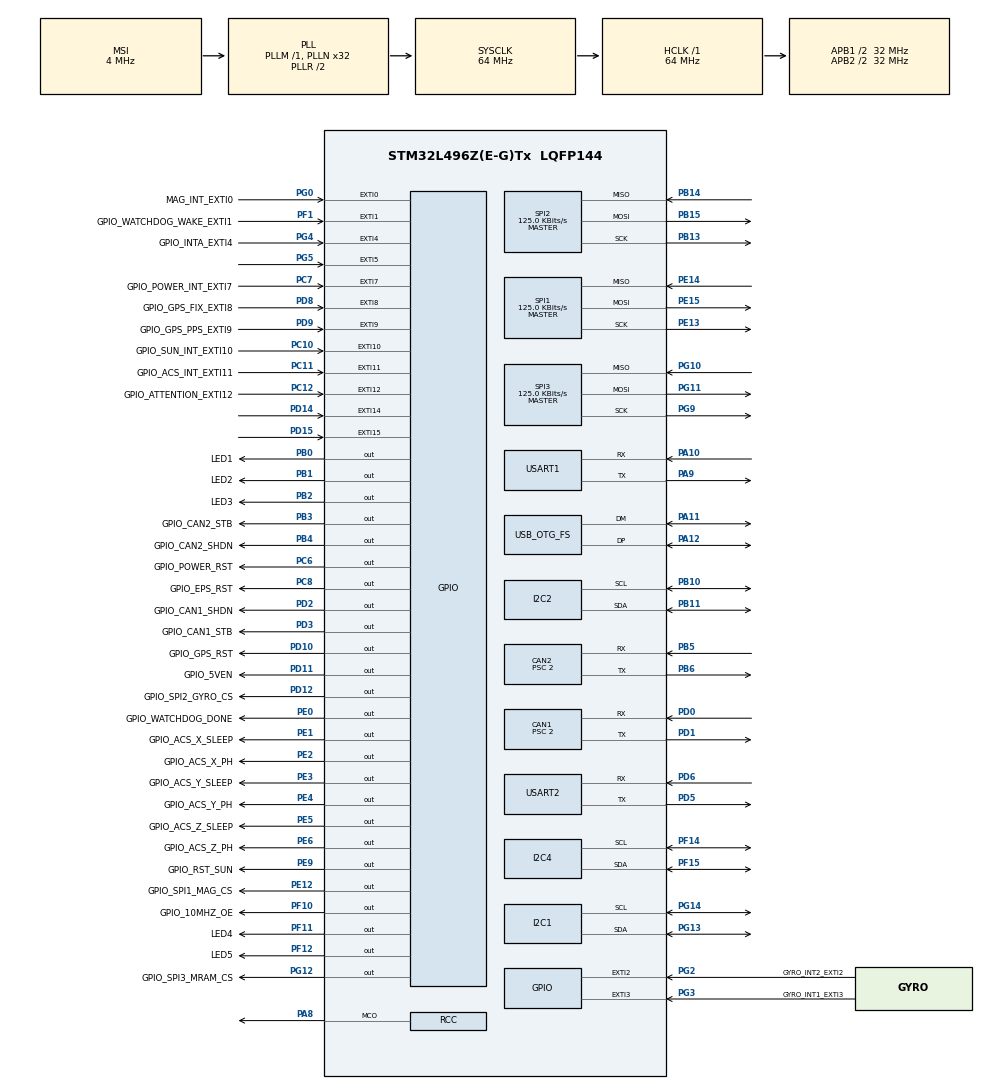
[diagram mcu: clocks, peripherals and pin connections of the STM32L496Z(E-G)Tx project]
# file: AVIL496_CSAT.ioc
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CAN1.AWUM=ENABLE
CAN1.BS1=CAN_BS1_13TQ
CAN1.BS2=CAN_BS2_2TQ
CAN1.CalculateBaudRate=1000000
CAN1.CalculateTimeBit=1000
CAN1.CalculateTimeQuantum=62.5
CAN1.Prescaler=2
CAN2.AWUM=ENABLE
CAN2.BS1=CAN_BS1_13TQ
CAN2.BS2=CAN_BS2_2TQ
CAN2.CalculateBaudRate=1000000
CAN2.CalculateTimeBit=1000
CAN2.CalculateTimeQuantum=62.5
CAN2.Prescaler=2
I2C1.Timing=0x00B07CB4
I2C2.Timing=0x00B07CB4
I2C4.Timing=0x00B07CB4
Mcu.Family=STM32L4
Mcu.Name=STM32L496Z(E-G)Tx
Mcu.Package=LQFP144
NVIC.CAN1_RX0_IRQn=true\:0\:0\:false\:false\:true\:true\:true\:true
NVIC.CAN1_RX1_IRQn=true\:0\:0\:false\:false\:true\:true\:true\:true
NVIC.CAN1_SCE_IRQn=true\:0\:0\:false\:false\:true\:true\:true\:true
NVIC.CAN2_RX0_IRQn=true\:0\:0\:false\:false\:true\:true\:true\:true
NVIC.CAN2_RX1_IRQn=true\:0\:0\:false\:false\:true\:true\:true\:true
NVIC.CAN2_SCE_IRQn=true\:0\:0\:false\:false\:true\:true\:true\:true
NVIC.EXTI0_IRQn=true\:0\:0\:false\:false\:true\:true\:true\:true
NVIC.EXTI15_10_IRQn=true\:0\:0\:false\:false\:true\:true\:true\:true
NVIC.EXTI1_IRQn=true\:0\:0\:false\:false\:true\:true\:true\:true
NVIC.EXTI2_IRQn=true\:0\:0\:false\:false\:true\:true\:true\:true
NVIC.EXTI3_IRQn=true\:0\:0\:false\:false\:true\:true\:true\:true
NVIC.EXTI4_IRQn=true\:0\:0\:false\:false\:true\:true\:true\:true
NVIC.EXTI9_5_IRQn=true\:0\:0\:false\:false\:true\:true\:true\:true
NVIC.OTG_FS_IRQn=true\:0\:0\:false\:false\:true\:false\:true\:true
NVIC.PriorityGroup=NVIC_PRIORITYGROUP_4
PA0.Signal=ADCx_IN5
PA1.Signal=ADCx_IN6
PA10.Mode=Asynchronous
PA10.Signal=USART1_RX
PA11.Mode=Device_Only
PA11.Signal=USB_OTG_FS_DM
PA12.Mode=Device_Only
PA12.Signal=USB_OTG_FS_DP
PA13\ (JTMS/SWDIO).Signal=SYS_JTMS-SWDIO
PA14\ (JTCK/SWCLK).Signal=SYS_JTCK-SWCLK
PA2.Signal=ADCx_IN7
PA3.Signal=ADCx_IN8
PA4.Signal=ADCx_IN9
PA5.Signal=ADCx_IN10
PA6.Signal=ADCx_IN11
PA7.Signal=ADCx_IN12
PA8.Mode=Clock-out
PA8.Signal=RCC_MCO
PA9.Mode=Asynchronous
PA9.Signal=USART1_TX
PB0.GPIO_Label=LED1
PB0.Signal=GPIO_Output
PB1.GPIO_Label=LED2
PB1.Signal=GPIO_Output
PB10.Mode=I2C
PB10.Signal=I2C2_SCL
PB11.Mode=I2C
PB11.Signal=I2C2_SDA
PB13.Mode=Full_Duplex_Master
PB13.Signal=SPI2_SCK
PB14.Mode=Full_Duplex_Master
PB14.Signal=SPI2_MISO
PB15.Mode=Full_Duplex_Master
PB15.Signal=SPI2_MOSI
PB2.GPIO_Label=LED3
PB2.Signal=GPIO_Output
PB3\ (JTDO/TRACESWO).GPIO_Label=GPIO_CAN2_STB
PB3\ (JTDO/TRACESWO).Signal=GPIO_Output
PB4\ (NJTRST).GPIO_Label=GPIO_CAN2_SHDN
PB4\ (NJTRST).Signal=GPIO_Output
PB5.Mode=CAN_Activate
PB5.Signal=CAN2_RX
PB6.Mode=CAN_Activate
PB6.Signal=CAN2_TX
PB8.GPIO_Label=TIM16_CH1_ACS_X
PB8.Signal=S_TIM16_CH1
PB9.GPIO_Label=TIM17_CH1_ACS_Y
PB9.Signal=S_TIM17_CH1
PC10.GPIO_Label=GPIO_SUN_INT_EXTI10
PC10.Signal=GPXTI10
PC11.GPIO_Label=GPIO_ACS_INT_EXTI11
PC11.Signal=GPXTI11
PC12.GPIO_Label=GPIO_ATTENTION_EXTI12
PC12.Signal=GPXTI12
PC14-OSC32_IN\ (PC14).Mode=LSE-External-Clock-Source
PC14-OSC32_IN\ (PC14).Signal=RCC_OSC32_IN
PC2.Signal=ADCx_IN3
PC3.Signal=ADCx_IN4
PC6.GPIO_Label=GPIO_POWER_RST
PC6.Signal=GPIO_Output
PC7.GPIO_Label=GPIO_POWER_INT_EXTI7
PC7.Signal=GPXTI7
PC8.GPIO_Label=GPIO_EPS_RST
PC8.Signal=GPIO_Output
PD0.Mode=CAN_Activate
PD0.Signal=CAN1_RX
PD1.Mode=CAN_Activate
PD1.Signal=CAN1_TX
PD10.GPIO_Label=GPIO_GPS_RST
PD10.Signal=GPIO_Output
PD11.GPIO_Label=GPIO_5VEN
PD11.Signal=GPIO_Output
PD12.GPIO_Label=GPIO_SPI2_GYRO_CS
PD12.PinState=GPIO_PIN_SET
PD12.Signal=GPIO_Output
PD14.Signal=GPXTI14
PD15.Signal=GPXTI15
PD2.GPIO_Label=GPIO_CAN1_SHDN
PD2.Signal=GPIO_Output
PD3.GPIO_Label=GPIO_CAN1_STB
PD3.Signal=GPIO_Output
PD5.Mode=Asynchronous
PD5.Signal=USART2_TX
PD6.Mode=Asynchronous
PD6.Signal=USART2_RX
PD8.GPIO_Label=GPIO_GPS_FIX_EXTI8
PD8.Signal=GPXTI8
PD9.GPIO_Label=GPIO_GPS_PPS_EXTI9
PD9.Signal=GPXTI9
PE0.GPIO_Label=GPIO_WATCHDOG_DONE
PE0.Signal=GPIO_Output
PE1.GPIO_Label=GPIO_ACS_X_SLEEP
PE1.Signal=GPIO_Output
PE12.GPIO_Label=GPIO_SPI1_MAG_CS
PE12.PinState=GPIO_PIN_SET
PE12.Signal=GPIO_Output
PE13.Mode=Full_Duplex_Master
PE13.Signal=SPI1_SCK
PE14.Mode=Full_Duplex_Master
PE14.Signal=SPI1_MISO
PE15.Mode=Full_Duplex_Master
PE15.Signal=SPI1_MOSI
PE2.GPIO_Label=GPIO_ACS_X_PH
PE2.Signal=GPIO_Output
PE3.GPIO_Label=GPIO_ACS_Y_SLEEP
PE3.Signal=GPIO_Output
PE4.GPIO_Label=GPIO_ACS_Y_PH
PE4.Signal=GPIO_Output
PE5.GPIO_Label=GPIO_ACS_Z_SLEEP
PE5.Signal=GPIO_Output
PE6.GPIO_Label=GPIO_ACS_Z_PH
PE6.Signal=GPIO_Output
PE9.GPIO_Label=GPIO_RST_SUN
PE9.Signal=GPIO_Output
PF1.GPIO_Label=GPIO_WATCHDOG_WAKE_EXTI1
PF1.GPIO_ModeDefaultEXTI=GPIO_MODE_IT_RISING
PF1.Signal=GPXTI1
PF10.GPIO_Label=GPIO_10MHZ_OE
PF10.Signal=GPIO_Output
PF11.GPIO_Label=LED4
PF11.Signal=GPIO_Output
PF12.GPIO_Label=LED5
PF12.Signal=GPIO_Output
PF14.Mode=I2C
PF14.Signal=I2C4_SCL
PF15.Mode=I2C
PF15.Signal=I2C4_SDA
PF9.GPIO_Label=TIM15_CHi1_ACS_Z
PF9.Signal=S_TIM15_CH1
PG0.GPIO_Label=MAG_INT_EXTI0
PG0.Signal=GPXTI0
PG10.Mode=Full_Duplex_Master
PG10.Signal=SPI3_MISO
PG11.Mode=Full_Duplex_Master
PG11.Signal=SPI3_MOSI
PG12.GPIO_Label=GPIO_SPI3_MRAM_CS
PG12.Signal=GPIO_Output
PG13.Mode=I2C
PG13.Signal=I2C1_SDA
PG14.Mode=I2C
PG14.Signal=I2C1_SCL
PG2.GPIO_Label=GYRO_INT2_EXTI2
PG2.Signal=GPXTI2
PG3.GPIO_Label=GYRO_INT1_EXTI3
PG3.Signal=GPXTI3
PG4.GPIO_Label=GPIO_INTA_EXTI4
PG4.Signal=GPXTI4
PG5.Signal=GPXTI5
PG9.Mode=Full_Duplex_Master
PG9.Signal=SPI3_SCK
PH0-OSC_IN\ (PH0).Signal=RCC_OSC_IN
ProjectManager.HeapSize=0x200
ProjectManager.StackSize=0x400
ProjectManager.TargetToolchain=STM32CubeIDE
RCC.ADCFreq_Value=48000000
RCC.AHBFreq_Value=64000000
RCC.APB1CLKDivider=RCC_HCLK_DIV2
RCC.APB1Freq_Value=32000000
RCC.APB1TimFreq_Value=64000000
RCC.APB2CLKDivider=RCC_HCLK_DIV2
RCC.APB2Freq_Value=32000000
RCC.APB2TimFreq_Value=64000000
RCC.CortexFreq_Value=64000000
RCC.HCLKFreq_Value=64000000
RCC.HSE_VALUE=8000000
RCC.HSI48_VALUE=48000000
RCC.HSI_VALUE=16000000
RCC.LSE_VALUE=32768
RCC.MSI_VALUE=4000000
RCC.PLLN=32
RCC.PLLSAI1N=24
RCC.SYSCLKFreq_VALUE=64000000
RCC.SYSCLKSource=RCC_SYSCLKSOURCE_PLLCLK
RCC.USBFreq_Value=48000000
RCC.VCOOutputFreq_Value=128000000
SH.ADCx_IN10.0=ADC1_IN10
SH.ADCx_IN11.0=ADC1_IN11
SH.ADCx_IN12.0=ADC1_IN12
SH.ADCx_IN3.0=ADC1_IN3
SH.ADCx_IN4.0=ADC1_IN4
SH.ADCx_IN5.0=ADC1_IN5
SH.ADCx_IN6.0=ADC1_IN6
SH.ADCx_IN7.0=ADC1_IN7
SH.ADCx_IN8.0=ADC1_IN8
SH.ADCx_IN9.0=ADC1_IN9
SH.S_TIM15_CH1.0=TIM15_CH1
SH.S_TIM16_CH1.0=TIM16_CH1
SH.S_TIM17_CH1.0=TIM17_CH1
SPI1.BaudRatePrescaler=SPI_BAUDRATEPRESCALER_256
SPI1.CalculateBaudRate=125.0 KBits/s
SPI1.DataSize=SPI_DATASIZE_8BIT
SPI1.Direction=SPI_DIRECTION_2LINES
SPI1.Mode=SPI_MODE_MASTER
SPI1.VirtualType=VM_MASTER
SPI2.BaudRatePrescaler=SPI_BAUDRATEPRESCALER_256
SPI2.CalculateBaudRate=125.0 KBits/s
SPI2.DataSize=SPI_DATASIZE_8BIT
SPI2.Direction=SPI_DIRECTION_2LINES
SPI2.Mode=SPI_MODE_MASTER
SPI2.VirtualType=VM_MASTER
SPI3.BaudRatePrescaler=SPI_BAUDRATEPRESCALER_256
SPI3.CalculateBaudRate=125.0 KBits/s
SPI3.DataSize=SPI_DATASIZE_8BIT
SPI3.Direction=SPI_DIRECTION_2LINES
SPI3.Mode=SPI_MODE_MASTER
SPI3.VirtualType=VM_MASTER
USART1.VirtualMode-Asynchronous=VM_ASYNC
USART2.VirtualMode-Asynchronous=VM_ASYNC
USB_DEVICE.CLASS_NAME_FS=CDC
USB_DEVICE.VirtualMode=Cdc
USB_DEVICE.VirtualModeFS=Cdc_FS
USB_OTG_FS.VirtualMode=Device_Only
VP_RTC_VS_RTC_Activate.Mode=RTC_Enabled
VP_USB_DEVICE_VS_USB_DEVICE_CDC_FS.Mode=CDC_FS
board=custom

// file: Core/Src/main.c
/* USER CODE BEGIN Header */
/**
  ******************************************************************************
  * @file           : main.c
  * @brief          : Main program body
  ******************************************************************************
  * @attention
  *
  * Copyright (c) 2025 STMicroelectronics.
  * All rights reserved.
  *
  * This software is licensed under terms that can be found in the LICENSE file
  * in the root directory of this software component.
  * If no LICENSE file comes with this software, it is provided AS-IS.
  *
  ******************************************************************************
  */
/* USER CODE END Header */
#include "main.h"
#include "usb_device.h"

/* USER CODE BEGIN Includes */
#include "cppmain.h"
#include "usbd_cdc_if.h"
/* USER CODE END Includes */

CAN_HandleTypeDef hcan1;
CAN_HandleTypeDef hcan2;

I2C_HandleTypeDef hi2c1;
I2C_HandleTypeDef hi2c2;
I2C_HandleTypeDef hi2c4;

RTC_HandleTypeDef hrtc;

SPI_HandleTypeDef hspi1;
SPI_HandleTypeDef hspi2;
SPI_HandleTypeDef hspi3;

UART_HandleTypeDef huart1;
UART_HandleTypeDef huart2;

void SystemClock_Config(void);
static void MX_GPIO_Init(void);
static void MX_CAN1_Init(void);
static void MX_CAN2_Init(void);
static void MX_I2C1_Init(void);
static void MX_I2C2_Init(void);
static void MX_I2C4_Init(void);
static void MX_USART1_UART_Init(void);
static void MX_USART2_UART_Init(void);
static void MX_RTC_Init(void);
static void MX_SPI1_Init(void);
static void MX_SPI2_Init(void);
static void MX_SPI3_Init(void);
/* USER CODE BEGIN PFP */
void SendWatchDogDone();
/* USER CODE END PFP */

/* USER CODE BEGIN 0 */
extern int getentropy(void* buffer, size_t length) {
    (void)buffer;
    (void)length;
    return -1; // ENOSYS: Function not implemented
}
/* USER CODE END 0 */

int main(void)
{

  /* MCU Configuration--------------------------------------------------------*/

  /* Reset of all peripherals, Initializes the Flash interface and the Systick. */
  HAL_Init();

  /* Configure the system clock */
  SystemClock_Config();

  /* Initialize all configured peripherals */
  MX_GPIO_Init();
  MX_CAN1_Init();
  MX_CAN2_Init();
  MX_I2C1_Init();
  MX_I2C2_Init();
  MX_I2C4_Init();
  MX_USART1_UART_Init();
  MX_USART2_UART_Init();
  MX_USB_DEVICE_Init();
  MX_RTC_Init();
  MX_SPI1_Init();
  MX_SPI2_Init();
  MX_SPI3_Init();
  /* USER CODE BEGIN 2 */
  SendWatchDogDone();
  cppmain();
  /* USER CODE END 2 */

  /* Infinite loop */
  while (1)
  {

  }
}

void SystemClock_Config(void)
{
  RCC_OscInitTypeDef RCC_OscInitStruct = {0};
  RCC_ClkInitTypeDef RCC_ClkInitStruct = {0};

  /** Configure the main internal regulator output voltage
  */
  if (HAL_PWREx_ControlVoltageScaling(PWR_REGULATOR_VOLTAGE_SCALE1) != HAL_OK)
  {
    Error_Handler();
  }

  /** Initializes the RCC Oscillators according to the specified parameters
  * in the RCC_OscInitTypeDef structure.
  */
  RCC_OscInitStruct.OscillatorType = RCC_OSCILLATORTYPE_LSI|RCC_OSCILLATORTYPE_LSE
                              |RCC_OSCILLATORTYPE_MSI;
  RCC_OscInitStruct.LSEState = RCC_LSE_BYPASS;
  RCC_OscInitStruct.LSIState = RCC_LSI_ON;
  RCC_OscInitStruct.MSIState = RCC_MSI_ON;
  RCC_OscInitStruct.MSICalibrationValue = 0;
  RCC_OscInitStruct.MSIClockRange = RCC_MSIRANGE_6;
  RCC_OscInitStruct.PLL.PLLState = RCC_PLL_ON;
  RCC_OscInitStruct.PLL.PLLSource = RCC_PLLSOURCE_MSI;
  RCC_OscInitStruct.PLL.PLLM = 1;
  RCC_OscInitStruct.PLL.PLLN = 32;
  RCC_OscInitStruct.PLL.PLLP = RCC_PLLP_DIV2;
  RCC_OscInitStruct.PLL.PLLQ = RCC_PLLQ_DIV2;
  RCC_OscInitStruct.PLL.PLLR = RCC_PLLR_DIV2;
  if (HAL_RCC_OscConfig(&RCC_OscInitStruct) != HAL_OK)
  {
    Error_Handler();
  }

  /** Initializes the CPU, AHB and APB buses clocks
  */
  RCC_ClkInitStruct.ClockType = RCC_CLOCKTYPE_HCLK|RCC_CLOCKTYPE_SYSCLK
                              |RCC_CLOCKTYPE_PCLK1|RCC_CLOCKTYPE_PCLK2;
  RCC_ClkInitStruct.SYSCLKSource = RCC_SYSCLKSOURCE_PLLCLK;
  RCC_ClkInitStruct.AHBCLKDivider = RCC_SYSCLK_DIV1;
  RCC_ClkInitStruct.APB1CLKDivider = RCC_HCLK_DIV2;
  RCC_ClkInitStruct.APB2CLKDivider = RCC_HCLK_DIV2;

  if (HAL_RCC_ClockConfig(&RCC_ClkInitStruct, FLASH_LATENCY_3) != HAL_OK)
  {
    Error_Handler();
  }
  HAL_RCC_MCOConfig(RCC_MCO1, RCC_MCO1SOURCE_SYSCLK, RCC_MCODIV_1);

  /** Enable MSI Auto calibration
  */
  HAL_RCCEx_EnableMSIPLLMode();
}

static void MX_CAN1_Init(void)
{

  hcan1.Instance = CAN1;
  hcan1.Init.Prescaler = 2;
  hcan1.Init.Mode = CAN_MODE_NORMAL;
  hcan1.Init.SyncJumpWidth = CAN_SJW_1TQ;
  hcan1.Init.TimeSeg1 = CAN_BS1_13TQ;
  hcan1.Init.TimeSeg2 = CAN_BS2_2TQ;
  hcan1.Init.TimeTriggeredMode = DISABLE;
  hcan1.Init.AutoBusOff = DISABLE;
  hcan1.Init.AutoWakeUp = ENABLE;
  hcan1.Init.AutoRetransmission = DISABLE;
  hcan1.Init.ReceiveFifoLocked = DISABLE;
  hcan1.Init.TransmitFifoPriority = DISABLE;
  if (HAL_CAN_Init(&hcan1) != HAL_OK)
  {
    Error_Handler();
  }

}

static void MX_CAN2_Init(void)
{

  hcan2.Instance = CAN2;
  hcan2.Init.Prescaler = 2;
  hcan2.Init.Mode = CAN_MODE_NORMAL;
  hcan2.Init.SyncJumpWidth = CAN_SJW_1TQ;
  hcan2.Init.TimeSeg1 = CAN_BS1_13TQ;
  hcan2.Init.TimeSeg2 = CAN_BS2_2TQ;
  hcan2.Init.TimeTriggeredMode = DISABLE;
  hcan2.Init.AutoBusOff = DISABLE;
  hcan2.Init.AutoWakeUp = ENABLE;
  hcan2.Init.AutoRetransmission = DISABLE;
  hcan2.Init.ReceiveFifoLocked = DISABLE;
  hcan2.Init.TransmitFifoPriority = DISABLE;
  if (HAL_CAN_Init(&hcan2) != HAL_OK)
  {
    Error_Handler();
  }

}

static void MX_I2C1_Init(void)
{

  hi2c1.Instance = I2C1;
  hi2c1.Init.Timing = 0x00B07CB4;
  hi2c1.Init.OwnAddress1 = 0;
  hi2c1.Init.AddressingMode = I2C_ADDRESSINGMODE_7BIT;
  hi2c1.Init.DualAddressMode = I2C_DUALADDRESS_DISABLE;
  hi2c1.Init.OwnAddress2 = 0;
  hi2c1.Init.OwnAddress2Masks = I2C_OA2_NOMASK;
  hi2c1.Init.GeneralCallMode = I2C_GENERALCALL_DISABLE;
  hi2c1.Init.NoStretchMode = I2C_NOSTRETCH_DISABLE;
  if (HAL_I2C_Init(&hi2c1) != HAL_OK)
  {
    Error_Handler();
  }

  /** Configure Analogue filter
  */
  if (HAL_I2CEx_ConfigAnalogFilter(&hi2c1, I2C_ANALOGFILTER_ENABLE) != HAL_OK)
  {
    Error_Handler();
  }

  /** Configure Digital filter
  */
  if (HAL_I2CEx_ConfigDigitalFilter(&hi2c1, 0) != HAL_OK)
  {
    Error_Handler();
  }

}

static void MX_I2C2_Init(void)
{

  hi2c2.Instance = I2C2;
  hi2c2.Init.Timing = 0x00B07CB4;
  hi2c2.Init.OwnAddress1 = 0;
  hi2c2.Init.AddressingMode = I2C_ADDRESSINGMODE_7BIT;
  hi2c2.Init.DualAddressMode = I2C_DUALADDRESS_DISABLE;
  hi2c2.Init.OwnAddress2 = 0;
  hi2c2.Init.OwnAddress2Masks = I2C_OA2_NOMASK;
  hi2c2.Init.GeneralCallMode = I2C_GENERALCALL_DISABLE;
  hi2c2.Init.NoStretchMode = I2C_NOSTRETCH_DISABLE;
  if (HAL_I2C_Init(&hi2c2) != HAL_OK)
  {
    Error_Handler();
  }

  /** Configure Analogue filter
  */
  if (HAL_I2CEx_ConfigAnalogFilter(&hi2c2, I2C_ANALOGFILTER_ENABLE) != HAL_OK)
  {
    Error_Handler();
  }

  /** Configure Digital filter
  */
  if (HAL_I2CEx_ConfigDigitalFilter(&hi2c2, 0) != HAL_OK)
  {
    Error_Handler();
  }

}

static void MX_I2C4_Init(void)
{

  hi2c4.Instance = I2C4;
  hi2c4.Init.Timing = 0x00B07CB4;
  hi2c4.Init.OwnAddress1 = 0;
  hi2c4.Init.AddressingMode = I2C_ADDRESSINGMODE_7BIT;
  hi2c4.Init.DualAddressMode = I2C_DUALADDRESS_DISABLE;
  hi2c4.Init.OwnAddress2 = 0;
  hi2c4.Init.OwnAddress2Masks = I2C_OA2_NOMASK;
  hi2c4.Init.GeneralCallMode = I2C_GENERALCALL_DISABLE;
  hi2c4.Init.NoStretchMode = I2C_NOSTRETCH_DISABLE;
  if (HAL_I2C_Init(&hi2c4) != HAL_OK)
  {
    Error_Handler();
  }

  /** Configure Analogue filter
  */
  if (HAL_I2CEx_ConfigAnalogFilter(&hi2c4, I2C_ANALOGFILTER_ENABLE) != HAL_OK)
  {
    Error_Handler();
  }

  /** Configure Digital filter
  */
  if (HAL_I2CEx_ConfigDigitalFilter(&hi2c4, 0) != HAL_OK)
  {
    Error_Handler();
  }

}

static void MX_RTC_Init(void)
{

  /** Initialize RTC Only
  */
  hrtc.Instance = RTC;
  hrtc.Init.HourFormat = RTC_HOURFORMAT_24;
  hrtc.Init.AsynchPrediv = 127;
  hrtc.Init.SynchPrediv = 255;
  hrtc.Init.OutPut = RTC_OUTPUT_DISABLE;
  hrtc.Init.OutPutRemap = RTC_OUTPUT_REMAP_NONE;
  hrtc.Init.OutPutPolarity = RTC_OUTPUT_POLARITY_HIGH;
  hrtc.Init.OutPutType = RTC_OUTPUT_TYPE_OPENDRAIN;
  if (HAL_RTC_Init(&hrtc) != HAL_OK)
  {
    Error_Handler();
  }

}

static void MX_SPI1_Init(void)
{

  /* SPI1 parameter configuration*/
  hspi1.Instance = SPI1;
  hspi1.Init.Mode = SPI_MODE_MASTER;
  hspi1.Init.Direction = SPI_DIRECTION_2LINES;
  hspi1.Init.DataSize = SPI_DATASIZE_8BIT;
  hspi1.Init.CLKPolarity = SPI_POLARITY_LOW;
  hspi1.Init.CLKPhase = SPI_PHASE_1EDGE;
  hspi1.Init.NSS = SPI_NSS_SOFT;
  hspi1.Init.BaudRatePrescaler = SPI_BAUDRATEPRESCALER_256;
  hspi1.Init.FirstBit = SPI_FIRSTBIT_MSB;
  hspi1.Init.TIMode = SPI_TIMODE_DISABLE;
  hspi1.Init.CRCCalculation = SPI_CRCCALCULATION_DISABLE;
  hspi1.Init.CRCPolynomial = 7;
  hspi1.Init.CRCLength = SPI_CRC_LENGTH_DATASIZE;
  hspi1.Init.NSSPMode = SPI_NSS_PULSE_ENABLE;
  if (HAL_SPI_Init(&hspi1) != HAL_OK)
  {
    Error_Handler();
  }

}

static void MX_SPI2_Init(void)
{

  /* SPI2 parameter configuration*/
  hspi2.Instance = SPI2;
  hspi2.Init.Mode = SPI_MODE_MASTER;
  hspi2.Init.Direction = SPI_DIRECTION_2LINES;
  hspi2.Init.DataSize = SPI_DATASIZE_8BIT;
  hspi2.Init.CLKPolarity = SPI_POLARITY_LOW;
  hspi2.Init.CLKPhase = SPI_PHASE_1EDGE;
  hspi2.Init.NSS = SPI_NSS_SOFT;
  hspi2.Init.BaudRatePrescaler = SPI_BAUDRATEPRESCALER_256;
  hspi2.Init.FirstBit = SPI_FIRSTBIT_MSB;
  hspi2.Init.TIMode = SPI_TIMODE_DISABLE;
  hspi2.Init.CRCCalculation = SPI_CRCCALCULATION_DISABLE;
  hspi2.Init.CRCPolynomial = 7;
  hspi2.Init.CRCLength = SPI_CRC_LENGTH_DATASIZE;
  hspi2.Init.NSSPMode = SPI_NSS_PULSE_ENABLE;
  if (HAL_SPI_Init(&hspi2) != HAL_OK)
  {
    Error_Handler();
  }

}

static void MX_SPI3_Init(void)
{

  /* SPI3 parameter configuration*/
  hspi3.Instance = SPI3;
  hspi3.Init.Mode = SPI_MODE_MASTER;
  hspi3.Init.Direction = SPI_DIRECTION_2LINES;
  hspi3.Init.DataSize = SPI_DATASIZE_8BIT;
  hspi3.Init.CLKPolarity = SPI_POLARITY_LOW;
  hspi3.Init.CLKPhase = SPI_PHASE_1EDGE;
  hspi3.Init.NSS = SPI_NSS_SOFT;
  hspi3.Init.BaudRatePrescaler = SPI_BAUDRATEPRESCALER_256;
  hspi3.Init.FirstBit = SPI_FIRSTBIT_MSB;
  hspi3.Init.TIMode = SPI_TIMODE_DISABLE;
  hspi3.Init.CRCCalculation = SPI_CRCCALCULATION_DISABLE;
  hspi3.Init.CRCPolynomial = 7;
  hspi3.Init.CRCLength = SPI_CRC_LENGTH_DATASIZE;
  hspi3.Init.NSSPMode = SPI_NSS_PULSE_ENABLE;
  if (HAL_SPI_Init(&hspi3) != HAL_OK)
  {
    Error_Handler();
  }

}

static void MX_USART1_UART_Init(void)
{

  huart1.Instance = USART1;
  huart1.Init.BaudRate = 115200;
  huart1.Init.WordLength = UART_WORDLENGTH_8B;
  huart1.Init.StopBits = UART_STOPBITS_1;
  huart1.Init.Parity = UART_PARITY_NONE;
  huart1.Init.Mode = UART_MODE_TX_RX;
  huart1.Init.HwFlowCtl = UART_HWCONTROL_NONE;
  huart1.Init.OverSampling = UART_OVERSAMPLING_16;
  huart1.Init.OneBitSampling = UART_ONE_BIT_SAMPLE_DISABLE;
  huart1.AdvancedInit.AdvFeatureInit = UART_ADVFEATURE_NO_INIT;
  if (HAL_UART_Init(&huart1) != HAL_OK)
  {
    Error_Handler();
  }

}

static void MX_USART2_UART_Init(void)
{

  huart2.Instance = USART2;
  huart2.Init.BaudRate = 115200;
  huart2.Init.WordLength = UART_WORDLENGTH_8B;
  huart2.Init.StopBits = UART_STOPBITS_1;
  huart2.Init.Parity = UART_PARITY_NONE;
  huart2.Init.Mode = UART_MODE_TX_RX;
  huart2.Init.HwFlowCtl = UART_HWCONTROL_NONE;
  huart2.Init.OverSampling = UART_OVERSAMPLING_16;
  huart2.Init.OneBitSampling = UART_ONE_BIT_SAMPLE_DISABLE;
  huart2.AdvancedInit.AdvFeatureInit = UART_ADVFEATURE_NO_INIT;
  if (HAL_UART_Init(&huart2) != HAL_OK)
  {
    Error_Handler();
  }

}

static void MX_GPIO_Init(void)
{
  GPIO_InitTypeDef GPIO_InitStruct = {0};

  /* GPIO Ports Clock Enable */
  __HAL_RCC_GPIOE_CLK_ENABLE();
  __HAL_RCC_GPIOC_CLK_ENABLE();
  __HAL_RCC_GPIOF_CLK_ENABLE();
  __HAL_RCC_GPIOH_CLK_ENABLE();
  __HAL_RCC_GPIOA_CLK_ENABLE();
  __HAL_RCC_GPIOB_CLK_ENABLE();
  __HAL_RCC_GPIOG_CLK_ENABLE();
  __HAL_RCC_GPIOD_CLK_ENABLE();
  HAL_PWREx_EnableVddIO2();

  /*Configure GPIO pin Output Level */
  HAL_GPIO_WritePin(GPIOE, GPIO_ACS_X_PH_Pin|GPIO_ACS_Y_SLEEP_Pin|GPIO_ACS_Y_PH_Pin|GPIO_ACS_Z_SLEEP_Pin
                          |GPIO_ACS_Z_PH_Pin|GPIO_RST_SUN_Pin|GPIO_WATCHDOG_DONE_Pin|GPIO_ACS_X_SLEEP_Pin, GPIO_PIN_RESET);

  /*Configure GPIO pin Output Level */
  HAL_GPIO_WritePin(GPIOF, GPIO_10MHZ_OE_Pin|LED4_Pin|LED5_Pin, GPIO_PIN_RESET);

  /*Configure GPIO pin Output Level */
  HAL_GPIO_WritePin(GPIOB, LED1_Pin|LED2_Pin|LED3_Pin|GPIO_CAN2_STB_Pin
                          |GPIO_CAN2_SHDN_Pin, GPIO_PIN_RESET);

  /*Configure GPIO pin Output Level */
  HAL_GPIO_WritePin(GPIO_SPI1_MAG_CS_GPIO_Port, GPIO_SPI1_MAG_CS_Pin, GPIO_PIN_SET);

  /*Configure GPIO pin Output Level */
  HAL_GPIO_WritePin(GPIOD, GPIO_GPS_RST_Pin|GPIO_5VEN_Pin|GPIO_CAN1_SHDN_Pin|GPIO_CAN1_STB_Pin, GPIO_PIN_RESET);

  /*Configure GPIO pin Output Level */
  HAL_GPIO_WritePin(GPIO_SPI2_GYRO_CS_GPIO_Port, GPIO_SPI2_GYRO_CS_Pin, GPIO_PIN_SET);

  /*Configure GPIO pin Output Level */
  HAL_GPIO_WritePin(GPIOC, GPIO_POWER_RST_Pin|GPIO_EPS_RST_Pin, GPIO_PIN_RESET);

  /*Configure GPIO pin Output Level */
  HAL_GPIO_WritePin(GPIO_SPI3_MRAM_CS_GPIO_Port, GPIO_SPI3_MRAM_CS_Pin, GPIO_PIN_RESET);

  /*Configure GPIO pins : GPIO_ACS_X_PH_Pin GPIO_ACS_Y_SLEEP_Pin GPIO_ACS_Y_PH_Pin GPIO_ACS_Z_SLEEP_Pin
                           GPIO_ACS_Z_PH_Pin GPIO_RST_SUN_Pin GPIO_SPI1_MAG_CS_Pin GPIO_WATCHDOG_DONE_Pin
                           GPIO_ACS_X_SLEEP_Pin */
  GPIO_InitStruct.Pin = GPIO_ACS_X_PH_Pin|GPIO_ACS_Y_SLEEP_Pin|GPIO_ACS_Y_PH_Pin|GPIO_ACS_Z_SLEEP_Pin
                          |GPIO_ACS_Z_PH_Pin|GPIO_RST_SUN_Pin|GPIO_SPI1_MAG_CS_Pin|GPIO_WATCHDOG_DONE_Pin
                          |GPIO_ACS_X_SLEEP_Pin;
  GPIO_InitStruct.Mode = GPIO_MODE_OUTPUT_PP;
  GPIO_InitStruct.Pull = GPIO_NOPULL;
  GPIO_InitStruct.Speed = GPIO_SPEED_FREQ_LOW;
  HAL_GPIO_Init(GPIOE, &GPIO_InitStruct);

  /*Configure GPIO pin : GPIO_WATCHDOG_WAKE_EXTI1_Pin */
  GPIO_InitStruct.Pin = GPIO_WATCHDOG_WAKE_EXTI1_Pin;
  GPIO_InitStruct.Mode = GPIO_MODE_IT_RISING;
  GPIO_InitStruct.Pull = GPIO_NOPULL;
  HAL_GPIO_Init(GPIO_WATCHDOG_WAKE_EXTI1_GPIO_Port, &GPIO_InitStruct);

  /*Configure GPIO pin : TIM15_CHi1_ACS_Z_Pin */
  GPIO_InitStruct.Pin = TIM15_CHi1_ACS_Z_Pin;
  GPIO_InitStruct.Mode = GPIO_MODE_AF_PP;
  GPIO_InitStruct.Pull = GPIO_NOPULL;
  GPIO_InitStruct.Speed = GPIO_SPEED_FREQ_LOW;
  GPIO_InitStruct.Alternate = GPIO_AF14_TIM15;
  HAL_GPIO_Init(TIM15_CHi1_ACS_Z_GPIO_Port, &GPIO_InitStruct);

  /*Configure GPIO pins : GPIO_10MHZ_OE_Pin LED4_Pin LED5_Pin */
  GPIO_InitStruct.Pin = GPIO_10MHZ_OE_Pin|LED4_Pin|LED5_Pin;
  GPIO_InitStruct.Mode = GPIO_MODE_OUTPUT_PP;
  GPIO_InitStruct.Pull = GPIO_NOPULL;
  GPIO_InitStruct.Speed = GPIO_SPEED_FREQ_LOW;
  HAL_GPIO_Init(GPIOF, &GPIO_InitStruct);

  /*Configure GPIO pins : PC2 PC3 */
  GPIO_InitStruct.Pin = GPIO_PIN_2|GPIO_PIN_3;
  GPIO_InitStruct.Mode = GPIO_MODE_ANALOG;
  GPIO_InitStruct.Pull = GPIO_NOPULL;
  HAL_GPIO_Init(GPIOC, &GPIO_InitStruct);

  /*Configure GPIO pins : PA0 PA1 PA2 PA3
                           PA4 PA5 PA6 PA7 */
  GPIO_InitStruct.Pin = GPIO_PIN_0|GPIO_PIN_1|GPIO_PIN_2|GPIO_PIN_3
                          |GPIO_PIN_4|GPIO_PIN_5|GPIO_PIN_6|GPIO_PIN_7;
  GPIO_InitStruct.Mode = GPIO_MODE_ANALOG;
  GPIO_InitStruct.Pull = GPIO_NOPULL;
  HAL_GPIO_Init(GPIOA, &GPIO_InitStruct);

  /*Configure GPIO pins : LED1_Pin LED2_Pin LED3_Pin GPIO_CAN2_STB_Pin
                           GPIO_CAN2_SHDN_Pin */
  GPIO_InitStruct.Pin = LED1_Pin|LED2_Pin|LED3_Pin|GPIO_CAN2_STB_Pin
                          |GPIO_CAN2_SHDN_Pin;
  GPIO_InitStruct.Mode = GPIO_MODE_OUTPUT_PP;
  GPIO_InitStruct.Pull = GPIO_NOPULL;
  GPIO_InitStruct.Speed = GPIO_SPEED_FREQ_LOW;
  HAL_GPIO_Init(GPIOB, &GPIO_InitStruct);

  /*Configure GPIO pins : MAG_INT_EXTI0_Pin GYRO_INT2_EXTI2_Pin GYRO_INT1_EXTI3_Pin GPIO_INTA_EXTI4_Pin
                           PG5 */
  GPIO_InitStruct.Pin = MAG_INT_EXTI0_Pin|GYRO_INT2_EXTI2_Pin|GYRO_INT1_EXTI3_Pin|GPIO_INTA_EXTI4_Pin
                          |GPIO_PIN_5;
  GPIO_InitStruct.Mode = GPIO_MODE_IT_RISING;
  GPIO_InitStruct.Pull = GPIO_NOPULL;
  HAL_GPIO_Init(GPIOG, &GPIO_InitStruct);

  /*Configure GPIO pins : GPIO_GPS_FIX_EXTI8_Pin GPIO_GPS_PPS_EXTI9_Pin PD14 PD15 */
  GPIO_InitStruct.Pin = GPIO_GPS_FIX_EXTI8_Pin|GPIO_GPS_PPS_EXTI9_Pin|GPIO_PIN_14|GPIO_PIN_15;
  GPIO_InitStruct.Mode = GPIO_MODE_IT_RISING;
  GPIO_InitStruct.Pull = GPIO_NOPULL;
  HAL_GPIO_Init(GPIOD, &GPIO_InitStruct);

  /*Configure GPIO pins : GPIO_GPS_RST_Pin GPIO_5VEN_Pin GPIO_SPI2_GYRO_CS_Pin GPIO_CAN1_SHDN_Pin
                           GPIO_CAN1_STB_Pin */
  GPIO_InitStruct.Pin = GPIO_GPS_RST_Pin|GPIO_5VEN_Pin|GPIO_SPI2_GYRO_CS_Pin|GPIO_CAN1_SHDN_Pin
                          |GPIO_CAN1_STB_Pin;
  GPIO_InitStruct.Mode = GPIO_MODE_OUTPUT_PP;
  GPIO_InitStruct.Pull = GPIO_NOPULL;
  GPIO_InitStruct.Speed = GPIO_SPEED_FREQ_LOW;
  HAL_GPIO_Init(GPIOD, &GPIO_InitStruct);

  /*Configure GPIO pins : GPIO_POWER_RST_Pin GPIO_EPS_RST_Pin */
  GPIO_InitStruct.Pin = GPIO_POWER_RST_Pin|GPIO_EPS_RST_Pin;
  GPIO_InitStruct.Mode = GPIO_MODE_OUTPUT_PP;
  GPIO_InitStruct.Pull = GPIO_NOPULL;
  GPIO_InitStruct.Speed = GPIO_SPEED_FREQ_LOW;
  HAL_GPIO_Init(GPIOC, &GPIO_InitStruct);

  /*Configure GPIO pins : GPIO_POWER_INT_EXTI7_Pin GPIO_SUN_INT_EXTI10_Pin GPIO_ACS_INT_EXTI11_Pin GPIO_ATTENTION_EXTI12_Pin */
  GPIO_InitStruct.Pin = GPIO_POWER_INT_EXTI7_Pin|GPIO_SUN_INT_EXTI10_Pin|GPIO_ACS_INT_EXTI11_Pin|GPIO_ATTENTION_EXTI12_Pin;
  GPIO_InitStruct.Mode = GPIO_MODE_IT_RISING;
  GPIO_InitStruct.Pull = GPIO_NOPULL;
  HAL_GPIO_Init(GPIOC, &GPIO_InitStruct);

  /*Configure GPIO pin : PA8 */
  GPIO_InitStruct.Pin = GPIO_PIN_8;
  GPIO_InitStruct.Mode = GPIO_MODE_AF_PP;
  GPIO_InitStruct.Pull = GPIO_NOPULL;
  GPIO_InitStruct.Speed = GPIO_SPEED_FREQ_LOW;
  GPIO_InitStruct.Alternate = GPIO_AF0_MCO;
  HAL_GPIO_Init(GPIOA, &GPIO_InitStruct);

  /*Configure GPIO pin : GPIO_SPI3_MRAM_CS_Pin */
  GPIO_InitStruct.Pin = GPIO_SPI3_MRAM_CS_Pin;
  GPIO_InitStruct.Mode = GPIO_MODE_OUTPUT_PP;
  GPIO_InitStruct.Pull = GPIO_NOPULL;
  GPIO_InitStruct.Speed = GPIO_SPEED_FREQ_LOW;
  HAL_GPIO_Init(GPIO_SPI3_MRAM_CS_GPIO_Port, &GPIO_InitStruct);

  /*Configure GPIO pin : TIM16_CH1_ACS_X_Pin */
  GPIO_InitStruct.Pin = TIM16_CH1_ACS_X_Pin;
  GPIO_InitStruct.Mode = GPIO_MODE_AF_PP;
  GPIO_InitStruct.Pull = GPIO_NOPULL;
  GPIO_InitStruct.Speed = GPIO_SPEED_FREQ_LOW;
  GPIO_InitStruct.Alternate = GPIO_AF14_TIM16;
  HAL_GPIO_Init(TIM16_CH1_ACS_X_GPIO_Port, &GPIO_InitStruct);

  /*Configure GPIO pin : TIM17_CH1_ACS_Y_Pin */
  GPIO_InitStruct.Pin = TIM17_CH1_ACS_Y_Pin;
  GPIO_InitStruct.Mode = GPIO_MODE_AF_PP;
  GPIO_InitStruct.Pull = GPIO_NOPULL;
  GPIO_InitStruct.Speed = GPIO_SPEED_FREQ_LOW;
  GPIO_InitStruct.Alternate = GPIO_AF14_TIM17;
  HAL_GPIO_Init(TIM17_CH1_ACS_Y_GPIO_Port, &GPIO_InitStruct);

  /* EXTI interrupt init*/
  HAL_NVIC_SetPriority(EXTI0_IRQn, 0, 0);
  HAL_NVIC_EnableIRQ(EXTI0_IRQn);

  HAL_NVIC_SetPriority(EXTI1_IRQn, 0, 0);
  HAL_NVIC_EnableIRQ(EXTI1_IRQn);

  HAL_NVIC_SetPriority(EXTI2_IRQn, 0, 0);
  HAL_NVIC_EnableIRQ(EXTI2_IRQn);

  HAL_NVIC_SetPriority(EXTI3_IRQn, 0, 0);
  HAL_NVIC_EnableIRQ(EXTI3_IRQn);

  HAL_NVIC_SetPriority(EXTI4_IRQn, 0, 0);
  HAL_NVIC_EnableIRQ(EXTI4_IRQn);

  HAL_NVIC_SetPriority(EXTI9_5_IRQn, 0, 0);
  HAL_NVIC_EnableIRQ(EXTI9_5_IRQn);

  HAL_NVIC_SetPriority(EXTI15_10_IRQn, 0, 0);
  HAL_NVIC_EnableIRQ(EXTI15_10_IRQn);

}

/* USER CODE BEGIN 4 */
/* USER CODE BEGIN 4 */
void SendWatchDogDone() {
	HAL_GPIO_WritePin(GPIO_WATCHDOG_DONE_GPIO_Port, GPIO_WATCHDOG_DONE_Pin,
			GPIO_PIN_SET);
	char *tx_buff1 = "Watchdog done set \r\n";
	CDC_Transmit_FS((uint8_t*) tx_buff1, strlen(tx_buff1));
	HAL_GPIO_WritePin(GPIO_WATCHDOG_DONE_GPIO_Port, GPIO_WATCHDOG_DONE_Pin,
			GPIO_PIN_RESET);
	char *tx_buff2 = "Watchdog done reset \r\n";
	CDC_Transmit_FS((uint8_t*) tx_buff2, strlen(tx_buff2));
}

void HAL_GPIO_EXTI_Callback(uint16_t GPIO_Pin)
{
	char* tx_buff0 = "HAL_GPIO_EXTI_Callback\r\n";
	CDC_Transmit_FS((uint8_t*) tx_buff0, strlen(tx_buff0));
	if(GPIO_Pin == GPIO_WATCHDOG_WAKE_EXTI1_Pin)
	{
		SendWatchDogDone();
  }
}
/* USER CODE END 4 */

void Error_Handler(void)
{
  __disable_irq();
  while (1)
  {
  }
}
